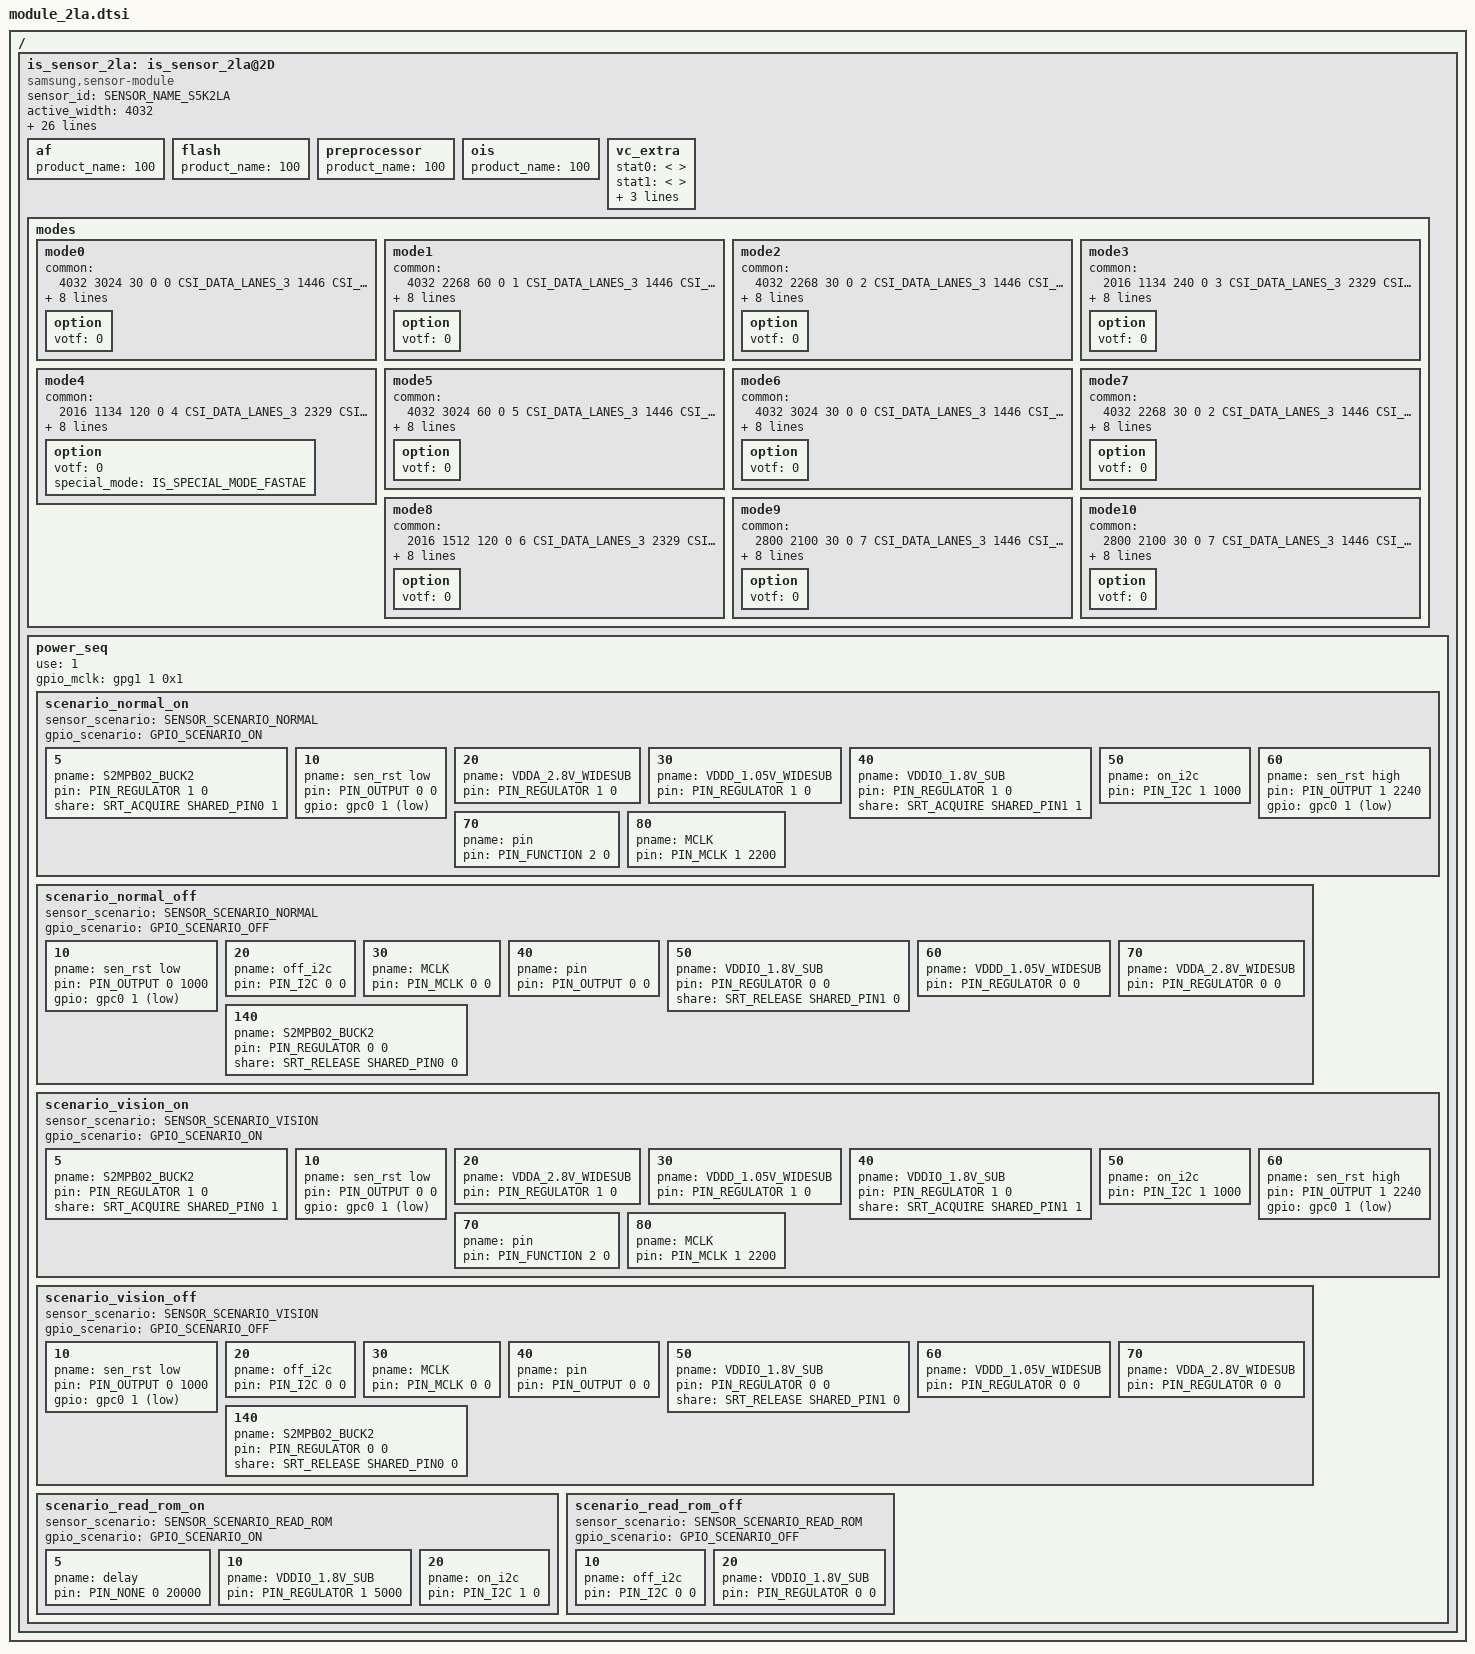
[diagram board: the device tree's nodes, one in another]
/*
 * SAMSUNG EXYNOSxxxx board camera device tree source
 *
 * Copyright (c) 2019 Samsung Electronics Co., Ltd.
 *		http://www.samsung.com
 *
 * This program is free software; you can redistribute it and/or modify
 * it under the terms of the GNU General Public License version 2 as
 * published by the Free Software Foundation.
 */

#include <dt-bindings/camera/exynos_is_dt.h>

/ {
	fragment@camera {
		target-path = "/";
		__overlay__ {
			is_sensor_2la: is_sensor_2la@2D {
				compatible = "samsung,sensor-module";

				/* common */
				sensor_id = <SENSOR_NAME_S5K2LA>;
				active_width = <4032>;
				active_height = <3024>;
				margin_left = <0>;
				margin_right = <0>;
				margin_top = <0>;
				margin_bottom = <0>;
				max_framerate = <240>;
				bitwidth = <10>;
				use_retention_mode = <SENSOR_RETENTION_UNSUPPORTED>;
				sensor_maker = "SLSI";
				sensor_name = "S5K2LA";
				setfile_name = "setfile_2la.bin";

				status = "okay";

				/* board */
				pinctrl-names = "pin0", "pin1", "pin2", "release";
				pinctrl-0 = <>;
				pinctrl-1 = <&sensor_mclk1_out>;
				pinctrl-2 = <&sensor_mclk1_fn>;
				pinctrl-3 = <>;

				position = <4>; /* Rear:0. Front:1, Tele:2 */
				id = <4>; /* is_sensor id */
				mclk_ch = <1>;
				mclk_freq = <19200>;
				sensor_i2c_ch = <4>; /* SENSOR_CONTROL_I2C4 */

				/* vendor */
				rom_type = <2>; /* ROM_TYPE_EEPROM */
				rom_id = <2>;
				rom_cal_index = <0>;
				rom_dualcal_id = <0>;
				rom_dualcal_index = <0>;

				/* peri */
				af {
					product_name = <100>;  /* NOTHING */
				};

				flash {
					product_name = <100>;  /* NOTHING */
				};

				preprocessor {
					product_name = <100>; /* NOTHING */
				};

				ois {
					product_name = <100>; /* NOTHING */
				};

				vc_extra {
					/* ex) statX = <stat_type, sensor_mode, max_width, max_height, max_element> */
					stat0 = </* not available */>;	/* VC_BUF_DATA_TYPE_SENSOR_STAT1 */
					stat1 = </* not available */>;	/* VC_BUF_DATA_TYPE_GENERAL_STAT1 */
					stat2 = </* not available */>;	/* VC_BUF_DATA_TYPE_SENSOR_STAT2 */
					stat3 = </* not available */>;	/* VC_BUF_DATA_TYPE_GENERAL_STAT2 */
					stat_vc = <2>; /* STAT out VC after CSIS link */
				};

				/* sensor modes */
				modes {
						/* common = <width, height, fps, settle, mode, lane, speed, interleave, lrte, pd_mode> */
						/* vcX = <map, hwformat, width, height, hwformat, type, width, height> */
					mode0 {/* 1_4032x3024 30fps */
						common = <4032 3024 30 0 0 CSI_DATA_LANES_3 1446 CSI_MODE_VC_ONLY LRTE_ENABLE PD_NONE>;
						vc0 = </* in */ 0 HW_FORMAT_RAW10 4032 3024	/* out */ HW_FORMAT_RAW10 VC_NOTHING 4032 3024>;
						vc1 = </* in */ 2 HW_FORMAT_UNKNOWN 0 0		/* out */ HW_FORMAT_UNKNOWN VC_NOTHING 0 0>;
						vc2 = </* in */ 1 HW_FORMAT_RAW10_POTF 4032 756	/* out */ HW_FORMAT_UNKNOWN VC_NOTHING 0 0>;
						vc3 = </* in */ 3 HW_FORMAT_UNKNOWN 0 0		/* out */ HW_FORMAT_UNKNOWN VC_NOTHING 0 0>;
						option { votf = <0>; };
					};
					mode1 {/* 2_4032x2268 60fps */
						common = <4032 2268 60 0 1 CSI_DATA_LANES_3 1446 CSI_MODE_VC_ONLY LRTE_ENABLE PD_NONE>;
						vc0 = </* in */ 0 HW_FORMAT_RAW10 4032 2268	/* out */ HW_FORMAT_RAW10 VC_NOTHING 4032 2268>;
						vc1 = </* in */ 2 HW_FORMAT_UNKNOWN 0 0		/* out */ HW_FORMAT_UNKNOWN VC_NOTHING 0 0>;
						vc2 = </* in */ 1 HW_FORMAT_RAW10_POTF 4032 756	/* out */ HW_FORMAT_UNKNOWN VC_NOTHING 0 0>;
						vc3 = </* in */ 3 HW_FORMAT_UNKNOWN 0 0		/* out */ HW_FORMAT_UNKNOWN VC_NOTHING 0 0>;
						option { votf = <0>; };
					};
					mode2 {/* 3_4032x2268 30fps */
						common = <4032 2268 30 0 2 CSI_DATA_LANES_3 1446 CSI_MODE_VC_ONLY LRTE_ENABLE PD_NONE>;
						vc0 = </* in */ 0 HW_FORMAT_RAW10 4032 2268	/* out */ HW_FORMAT_RAW10 VC_NOTHING 4032 2268>;
						vc1 = </* in */ 2 HW_FORMAT_UNKNOWN 0 0		/* out */ HW_FORMAT_UNKNOWN VC_NOTHING 0 0>;
						vc2 = </* in */ 1 HW_FORMAT_RAW10_POTF 4032 567	/* out */ HW_FORMAT_UNKNOWN VC_NOTHING 0 0>;
						vc3 = </* in */ 3 HW_FORMAT_UNKNOWN 0 0		/* out */ HW_FORMAT_UNKNOWN VC_NOTHING 0 0>;
						option { votf = <0>; };
					};
					mode3 {/* 4_2016x1134 240fps */
						common = <2016 1134 240 0 3 CSI_DATA_LANES_3 2329 CSI_MODE_VC_ONLY LRTE_DISABLE PD_NONE>;
						vc0 = </* in */ 0 HW_FORMAT_RAW10 2016 1134	/* out */ HW_FORMAT_RAW10 VC_NOTHING 2016 1134>;
						vc1 = </* in */ 2 HW_FORMAT_UNKNOWN 0 0		/* out */ HW_FORMAT_UNKNOWN VC_NOTHING 0 0>;
						vc2 = </* in */ 1 HW_FORMAT_RAW10_POTF 4032 567	/* out */ HW_FORMAT_UNKNOWN VC_NOTHING 0 0>;
						vc3 = </* in */ 3 HW_FORMAT_UNKNOWN 0 0		/* out */ HW_FORMAT_UNKNOWN VC_NOTHING 0 0>;
						option { votf = <0>; };
					};
					mode4 {/* 5_2016x1134 120fps */
						common = <2016 1134 120 0 4 CSI_DATA_LANES_3 2329 CSI_MODE_VC_ONLY LRTE_DISABLE PD_NONE>;
						vc0 = </* in */ 0 HW_FORMAT_RAW10 2016 1134	/* out */ HW_FORMAT_RAW10 VC_NOTHING 2016 1134>;
						vc1 = </* in */ 2 HW_FORMAT_UNKNOWN 0 0		/* out */ HW_FORMAT_UNKNOWN VC_NOTHING 0 0>;
						vc2 = </* in */ 1 HW_FORMAT_RAW10_POTF 2016 378	/* out */ HW_FORMAT_UNKNOWN VC_NOTHING 0 0>;
						vc3 = </* in */ 3 HW_FORMAT_UNKNOWN 0 0		/* out */ HW_FORMAT_UNKNOWN VC_NOTHING 0 0>;
						option { votf = <0>; special_mode = <IS_SPECIAL_MODE_FASTAE>; };
					};
					mode5 {/* 6_4032x3024 60fps */
						common = <4032 3024 60 0 5 CSI_DATA_LANES_3 1446 CSI_MODE_VC_ONLY LRTE_DISABLE PD_NONE>;
						vc0 = </* in */ 0 HW_FORMAT_RAW10 4032 3024	/* out */ HW_FORMAT_RAW10 VC_NOTHING 4032 3024>;
						vc1 = </* in */ 2 HW_FORMAT_UNKNOWN 0 0		/* out */ HW_FORMAT_UNKNOWN VC_NOTHING 0 0>;
						vc2 = </* in */ 1 HW_FORMAT_RAW10_POTF 2016 284	/* out */ HW_FORMAT_UNKNOWN VC_NOTHING 0 0>;
						vc3 = </* in */ 3 HW_FORMAT_UNKNOWN 0 0		/* out */ HW_FORMAT_UNKNOWN VC_NOTHING 0 0>;
						option { votf = <0>; };
					};
					mode6 {/* 1_4032x3024 30fps */
						common = <4032 3024 30 0 0 CSI_DATA_LANES_3 1446 CSI_MODE_VC_ONLY LRTE_DISABLE PD_NONE EX_LIVEFOCUS>;
						vc0 = </* in */ 0 HW_FORMAT_RAW10 4032 3024	/* out */ HW_FORMAT_RAW10 VC_NOTHING 4032 3024>;
						vc1 = </* in */ 2 HW_FORMAT_UNKNOWN 0 0		/* out */ HW_FORMAT_UNKNOWN VC_NOTHING 0 0>;
						vc2 = </* in */ 1 HW_FORMAT_RAW10_POTF 2016 284	/* out */ HW_FORMAT_UNKNOWN VC_NOTHING 0 0>;
						vc3 = </* in */ 3 HW_FORMAT_UNKNOWN 0 0		/* out */ HW_FORMAT_UNKNOWN VC_NOTHING 0 0>;
						option { votf = <0>; };
					};
					mode7 {/* 3_4032x2268 30fps */
						common = <4032 2268 30 0 2 CSI_DATA_LANES_3 1446 CSI_MODE_VC_ONLY LRTE_DISABLE PD_NONE EX_LIVEFOCUS>;
						vc0 = </* in */ 0 HW_FORMAT_RAW10 4032 2268	/* out */ HW_FORMAT_RAW10 VC_NOTHING 4032 2268>;
						vc1 = </* in */ 2 HW_FORMAT_UNKNOWN 0 0		/* out */ HW_FORMAT_UNKNOWN VC_NOTHING 0 0>;
						vc2 = </* in */ 1 HW_FORMAT_RAW10_POTF 2016 284	/* out */ HW_FORMAT_UNKNOWN VC_NOTHING 0 0>;
						vc3 = </* in */ 3 HW_FORMAT_UNKNOWN 0 0		/* out */ HW_FORMAT_UNKNOWN VC_NOTHING 0 0>;
						option { votf = <0>; };
					};
					mode8 {/* 10_2016x1512 120fps */
						common = <2016 1512 120 0 6 CSI_DATA_LANES_3 2329 CSI_MODE_VC_ONLY LRTE_DISABLE PD_NONE>;
						vc0 = </* in */ 0 HW_FORMAT_RAW10 2016 1512	/* out */ HW_FORMAT_RAW10 VC_NOTHING 2016 1512>;
						vc1 = </* in */ 2 HW_FORMAT_UNKNOWN 0 0		/* out */ HW_FORMAT_UNKNOWN VC_NOTHING 0 0>;
						vc2 = </* in */ 1 HW_FORMAT_RAW10_POTF 2016 284	/* out */ HW_FORMAT_UNKNOWN VC_NOTHING 0 0>;
						vc3 = </* in */ 3 HW_FORMAT_UNKNOWN 0 0		/* out */ HW_FORMAT_UNKNOWN VC_NOTHING 0 0>;
						option { votf = <0>; };
					};
					mode9 {/* 12_2800x2100 30fps */
						common = <2800 2100 30 0 7 CSI_DATA_LANES_3 1446 CSI_MODE_VC_ONLY LRTE_DISABLE PD_NONE EX_LIVEFOCUS>;
						vc0 = </* in */ 0 HW_FORMAT_RAW10 2800 2100	/* out */ HW_FORMAT_RAW10 VC_NOTHING 2800 2100>;
						vc1 = </* in */ 2 HW_FORMAT_UNKNOWN 0 0		/* out */ HW_FORMAT_UNKNOWN VC_NOTHING 0 0>;
						vc2 = </* in */ 1 HW_FORMAT_RAW10_POTF 2016 284	/* out */ HW_FORMAT_UNKNOWN VC_NOTHING 0 0>;
						vc3 = </* in */ 3 HW_FORMAT_UNKNOWN 0 0		/* out */ HW_FORMAT_UNKNOWN VC_NOTHING 0 0>;
						option { votf = <0>; };
					};

					mode10 {/* 12_2800x2100 30fps */
						common = <2800 2100 30 0 7 CSI_DATA_LANES_3 1446 CSI_MODE_VC_ONLY LRTE_DISABLE PD_NONE>;
						vc0 = </* in */ 0 HW_FORMAT_RAW10 2800 2100	/* out */ HW_FORMAT_RAW10 VC_NOTHING 2800 2100>;
						vc1 = </* in */ 2 HW_FORMAT_UNKNOWN 0 0		/* out */ HW_FORMAT_UNKNOWN VC_NOTHING 0 0>;
						vc2 = </* in */ 1 HW_FORMAT_RAW10_POTF 2016 284	/* out */ HW_FORMAT_UNKNOWN VC_NOTHING 0 0>;
						vc3 = </* in */ 3 HW_FORMAT_UNKNOWN 0 0		/* out */ HW_FORMAT_UNKNOWN VC_NOTHING 0 0>;
						option { votf = <0>; };
					};
				};

				power_seq {
					use = <1>;
					gpio_mclk = <&gpg1 1 0x1>;
					scenario_normal_on {
						sensor_scenario = <SENSOR_SCENARIO_NORMAL>;
						gpio_scenario = <GPIO_SCENARIO_ON>;

						/* A start node number should be over the 10 for reserved number 0~9. */
						/* pname = "name"; pin = <act value dealy voltage>; gpio = <gpx# # 0x1>; */
						5 { pname = "S2MPB02_BUCK2"; pin = <PIN_REGULATOR 1 0>; share = <SRT_ACQUIRE SHARED_PIN0 1>; };
						10 { pname = "sen_rst low"; pin = <PIN_OUTPUT 0 0>; gpio = <&gpc0 1 0x1>; };
						20 { pname = "VDDA_2.8V_WIDESUB"; pin = <PIN_REGULATOR 1 0>; };
						30 { pname = "VDDD_1.05V_WIDESUB"; pin = <PIN_REGULATOR 1 0>; };
						40 { pname = "VDDIO_1.8V_SUB"; pin = <PIN_REGULATOR 1 0>; share = <SRT_ACQUIRE SHARED_PIN1 1>; };
						50 { pname = "on_i2c"; pin = <PIN_I2C 1 1000>; };
						60 { pname = "sen_rst high"; pin = <PIN_OUTPUT 1 2240>; gpio = <&gpc0 1 0x1>; };
						70 { pname = "pin"; pin = <PIN_FUNCTION 2 0>; };
						80 { pname = "MCLK"; pin = <PIN_MCLK 1 2200>; };
					};

					scenario_normal_off {
						sensor_scenario = <SENSOR_SCENARIO_NORMAL>;
						gpio_scenario = <GPIO_SCENARIO_OFF>;

						/* A start node number should be over the 10 for reserved number 0~9. */
						/* pname = "name"; pin = <act value dealy voltage>; gpio = <gpx# # 0x1>; */
						10 { pname = "sen_rst low"; pin = <PIN_OUTPUT 0 1000>; gpio = <&gpc0 1 0x1>; };
						20 { pname = "off_i2c"; pin = <PIN_I2C 0 0>; };
						30 { pname = "MCLK"; pin = <PIN_MCLK 0 0>; };
						40 { pname = "pin"; pin = <PIN_OUTPUT 0 0>; };
						50 { pname = "VDDIO_1.8V_SUB"; pin = <PIN_REGULATOR 0 0>; share = <SRT_RELEASE SHARED_PIN1 0>; };
						60 { pname = "VDDD_1.05V_WIDESUB"; pin = <PIN_REGULATOR 0 0>; };
						70 { pname = "VDDA_2.8V_WIDESUB"; pin = <PIN_REGULATOR 0 0>; };
						140 { pname = "S2MPB02_BUCK2"; pin = <PIN_REGULATOR 0 0>; share = <SRT_RELEASE SHARED_PIN0 0>; };
					};

					scenario_vision_on {
						sensor_scenario = <SENSOR_SCENARIO_VISION>;
						gpio_scenario = <GPIO_SCENARIO_ON>;

						/* A start node number should be over the 10 for reserved number 0~9. */
						/* pname = "name"; pin = <act value dealy voltage>; gpio = <gpx# # 0x1>; */
						5 { pname = "S2MPB02_BUCK2"; pin = <PIN_REGULATOR 1 0>; share = <SRT_ACQUIRE SHARED_PIN0 1>; };
						10 { pname = "sen_rst low"; pin = <PIN_OUTPUT 0 0>; gpio = <&gpc0 1 0x1>; };
						20 { pname = "VDDA_2.8V_WIDESUB"; pin = <PIN_REGULATOR 1 0>; };
						30 { pname = "VDDD_1.05V_WIDESUB"; pin = <PIN_REGULATOR 1 0>; };
						40 { pname = "VDDIO_1.8V_SUB"; pin = <PIN_REGULATOR 1 0>; share = <SRT_ACQUIRE SHARED_PIN1 1>; };
						50 { pname = "on_i2c"; pin = <PIN_I2C 1 1000>; };
						60 { pname = "sen_rst high"; pin = <PIN_OUTPUT 1 2240>; gpio = <&gpc0 1 0x1>; };
						70 { pname = "pin"; pin = <PIN_FUNCTION 2 0>; };
						80 { pname = "MCLK"; pin = <PIN_MCLK 1 2200>; };
					};

					scenario_vision_off {
						sensor_scenario = <SENSOR_SCENARIO_VISION>;
						gpio_scenario = <GPIO_SCENARIO_OFF>;

						/* A start node number should be over the 10 for reserved number 0~9. */
						/* pname = "name"; pin = <act value dealy voltage>; gpio = <gpx# # 0x1>; */
						10 { pname = "sen_rst low"; pin = <PIN_OUTPUT 0 1000>; gpio = <&gpc0 1 0x1>; };
						20 { pname = "off_i2c"; pin = <PIN_I2C 0 0>; };
						30 { pname = "MCLK"; pin = <PIN_MCLK 0 0>; };
						40 { pname = "pin"; pin = <PIN_OUTPUT 0 0>; };
						50 { pname = "VDDIO_1.8V_SUB"; pin = <PIN_REGULATOR 0 0>; share = <SRT_RELEASE SHARED_PIN1 0>; };
						60 { pname = "VDDD_1.05V_WIDESUB"; pin = <PIN_REGULATOR 0 0>; };
						70 { pname = "VDDA_2.8V_WIDESUB"; pin = <PIN_REGULATOR 0 0>; };
						140 { pname = "S2MPB02_BUCK2"; pin = <PIN_REGULATOR 0 0>; share = <SRT_RELEASE SHARED_PIN0 0>; };
					};

					scenario_read_rom_on {
						sensor_scenario = <SENSOR_SCENARIO_READ_ROM>;
						gpio_scenario = <GPIO_SCENARIO_ON>;

						/* A start node number should be over the 10 for reserved number 0~9. */
						/* pname = "name"; pin = <act value dealy voltage>; gpio = <gpx# # 0x1>; */
						5 { pname = "delay"; pin = <PIN_NONE 0 20000>; };
						10 { pname = "VDDIO_1.8V_SUB"; pin = <PIN_REGULATOR 1 5000>; };
						20 { pname = "on_i2c"; pin = <PIN_I2C 1 0>; };
					};

					scenario_read_rom_off {
						sensor_scenario = <SENSOR_SCENARIO_READ_ROM>;
						gpio_scenario = <GPIO_SCENARIO_OFF>;

						/* A start node number should be over the 10 for reserved number 0~9. */
						/* pname = "name"; pin = <act value dealy voltage>; gpio = <gpx# # 0x1>; */
						10 { pname = "off_i2c"; pin = <PIN_I2C 0 0>; };
						20 { pname = "VDDIO_1.8V_SUB"; pin = <PIN_REGULATOR 0 0>; };
					};
				};
			};
		}; /* end of __overlay__ */
	}; /* end of fragment */
}; /* end of root */
